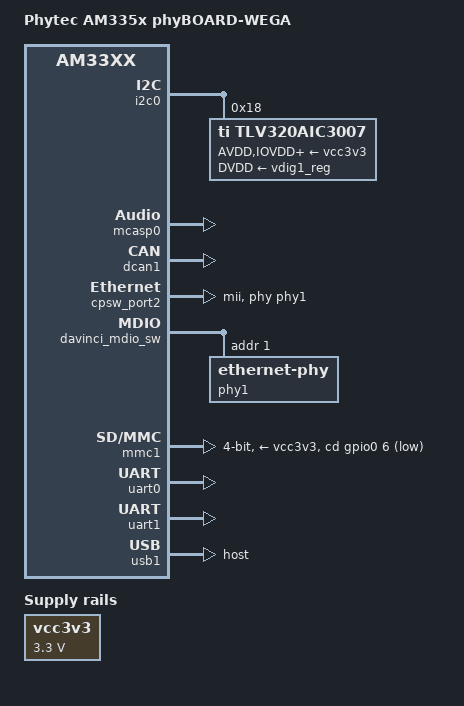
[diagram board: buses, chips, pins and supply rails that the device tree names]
/ {
	model = "Phytec AM335x phyBOARD-WEGA";
	compatible = "phytec,am335x-wega", "phytec,am335x-phycore-som", "ti,am33xx";
	sound: sound {
		compatible = "simple-audio-card";
		simple-audio-card,name = "snd-wega";
		simple-audio-card,format = "i2s";
		simple-audio-card,bitclock-master = <&sound_iface_main>;
		simple-audio-card,frame-master = <&sound_iface_main>;
		simple-audio-card,mclk-fs = <32>;
		simple-audio-card,widgets =
					"Line", "Line In",
					"Line", "Line Out",
					"Speaker", "Speaker";
		simple-audio-card,routing =
					"Line Out", "LLOUT",
					"Line Out", "RLOUT",
					"Speaker", "SPOP",
					"Speaker", "SPOM",
					"LINE1L", "Line In",
					"LINE1R", "Line In";
		simple-audio-card,cpu {
			sound-dai = <&mcasp0>;
		};
		sound_iface_main: simple-audio-card,codec {
			sound-dai = <&tlv320aic3007>;
			clocks = <&mcasp0_fck>;
		};
	};
	vcc3v3: fixedregulator1 {
		compatible = "regulator-fixed";
		regulator-name = "vcc3v3";
		regulator-min-microvolt = <3300000>;
		regulator-max-microvolt = <3300000>;
		regulator-boot-on;
	};
};
&am33xx_pinmux {
	mcasp0_pins: pinmux-mcasp0-pins {
		pinctrl-single,pins = <
			AM33XX_PADCONF(AM335X_PIN_MCASP0_AHCLKX, PIN_OUTPUT_PULLDOWN, MUX_MODE0)
			AM33XX_PADCONF(AM335X_PIN_MCASP0_ACLKX, PIN_INPUT_PULLDOWN, MUX_MODE0)
			AM33XX_PADCONF(AM335X_PIN_MCASP0_FSX, PIN_INPUT_PULLDOWN, MUX_MODE0)
			AM33XX_PADCONF(AM335X_PIN_MCASP0_AXR0, PIN_INPUT_PULLDOWN, MUX_MODE0)
			AM33XX_PADCONF(AM335X_PIN_MCASP0_AXR1, PIN_OUTPUT_PULLDOWN, MUX_MODE0)
		>;
	};
};
&i2c0 {
	tlv320aic3007: tlv320aic3007@18 {
		#sound-dai-cells = <0>;
		compatible = "ti,tlv320aic3007";
		reg = <0x18>;
		AVDD-supply = <&vcc3v3>;
		IOVDD-supply = <&vcc3v3>;
		DRVDD-supply = <&vcc3v3>;
		DVDD-supply = <&vdig1_reg>;
		status = "okay";
	};
};
&mcasp0 {
	#sound-dai-cells = <0>;
	pinctrl-names = "default";
	pinctrl-0 = <&mcasp0_pins>;
	op-mode = <0>;  
	tdm-slots = <2>;
	serial-dir = <
		2 1 0 0  
	>;
	tx-num-evt = <16>;
	rx-num-evt = <16>;
	status = "okay";
};
&am33xx_pinmux {
	dcan1_pins: pinmux-dcan1-pins {
		pinctrl-single,pins = <
			AM33XX_PADCONF(AM335X_PIN_UART0_CTSN, PIN_OUTPUT_PULLUP, MUX_MODE2)  
			AM33XX_PADCONF(AM335X_PIN_UART0_RTSN, PIN_INPUT_PULLUP, MUX_MODE2)  
		>;
	};
};
&dcan1 {
	pinctrl-names = "default";
	pinctrl-0 = <&dcan1_pins>;
	status = "okay";
};
&am33xx_pinmux {
	ethernet1_pins: pinmux-ethernet1-pins {
		pinctrl-single,pins = <
			AM33XX_PADCONF(AM335X_PIN_GPMC_A0, PIN_OUTPUT, MUX_MODE1)		 
			AM33XX_PADCONF(AM335X_PIN_GPMC_A1, PIN_INPUT_PULLDOWN, MUX_MODE1)	 
			AM33XX_PADCONF(AM335X_PIN_GPMC_A2, PIN_OUTPUT, MUX_MODE1)		 
			AM33XX_PADCONF(AM335X_PIN_GPMC_A3, PIN_OUTPUT, MUX_MODE1)		 
			AM33XX_PADCONF(AM335X_PIN_GPMC_A4, PIN_OUTPUT, MUX_MODE1)		 
			AM33XX_PADCONF(AM335X_PIN_GPMC_A5, PIN_OUTPUT, MUX_MODE1)		 
			AM33XX_PADCONF(AM335X_PIN_GPMC_A6, PIN_INPUT_PULLDOWN, MUX_MODE1)	 
			AM33XX_PADCONF(AM335X_PIN_GPMC_A7, PIN_INPUT_PULLDOWN, MUX_MODE1)	 
			AM33XX_PADCONF(AM335X_PIN_GPMC_A8, PIN_INPUT_PULLDOWN, MUX_MODE1)	 
			AM33XX_PADCONF(AM335X_PIN_GPMC_A9, PIN_INPUT_PULLDOWN, MUX_MODE1)	 
			AM33XX_PADCONF(AM335X_PIN_GPMC_A10, PIN_INPUT_PULLDOWN, MUX_MODE1)	 
			AM33XX_PADCONF(AM335X_PIN_GPMC_A11, PIN_INPUT_PULLDOWN, MUX_MODE1)	 
			AM33XX_PADCONF(AM335X_PIN_GPMC_WPN, PIN_INPUT_PULLDOWN, MUX_MODE1)	 
			AM33XX_PADCONF(AM335X_PIN_GPMC_BEN1, PIN_INPUT_PULLDOWN, MUX_MODE1)	 
		>;
	};
};
&cpsw_port2 {
	status = "okay";
	phy-handle = <&phy1>;
	phy-mode = "mii";
	ti,dual-emac-pvid = <2>;
};
&davinci_mdio_sw {
	phy1: ethernet-phy@1 {
		reg = <1>;
	};
};
&mac_sw {
	pinctrl-names = "default";
	pinctrl-0 = <&ethernet0_pins &ethernet1_pins>;
};
&am33xx_pinmux {
	mmc1_pins: pinmux-mmc1-pins {
		pinctrl-single,pins = <
			AM33XX_PADCONF(AM335X_PIN_MMC0_DAT3, PIN_INPUT_PULLUP, MUX_MODE0)
			AM33XX_PADCONF(AM335X_PIN_MMC0_DAT2, PIN_INPUT_PULLUP, MUX_MODE0)
			AM33XX_PADCONF(AM335X_PIN_MMC0_DAT1, PIN_INPUT_PULLUP, MUX_MODE0)
			AM33XX_PADCONF(AM335X_PIN_MMC0_DAT0, PIN_INPUT_PULLUP, MUX_MODE0)
			AM33XX_PADCONF(AM335X_PIN_MMC0_CLK, PIN_INPUT_PULLUP, MUX_MODE0)
			AM33XX_PADCONF(AM335X_PIN_MMC0_CMD, PIN_INPUT_PULLUP, MUX_MODE0)
			AM33XX_PADCONF(AM335X_PIN_SPI0_CS1, PIN_INPUT_PULLUP, MUX_MODE7)	 
		>;
	};
};
&mmc1 {
	vmmc-supply = <&vcc3v3>;
	bus-width = <4>;
	pinctrl-names = "default";
	pinctrl-0 = <&mmc1_pins>;
	cd-gpios = <&gpio0 6 GPIO_ACTIVE_LOW>;
	status = "okay";
};
&vdig1_reg {
	regulator-boot-on;
	regulator-always-on;
};
&am33xx_pinmux {
	uart0_pins: pinmux-uart0-pins {
		pinctrl-single,pins = <
			AM33XX_PADCONF(AM335X_PIN_UART0_RXD, PIN_INPUT_PULLUP, MUX_MODE0)
			AM33XX_PADCONF(AM335X_PIN_UART0_TXD, PIN_OUTPUT_PULLDOWN, MUX_MODE0)
		>;
	};
	uart1_pins: pinmux-uart1-pins {
		pinctrl-single,pins = <
			AM33XX_PADCONF(AM335X_PIN_UART1_RXD, PIN_INPUT_PULLUP, MUX_MODE0)
			AM33XX_PADCONF(AM335X_PIN_UART1_TXD, PIN_OUTPUT_PULLDOWN, MUX_MODE0)
			AM33XX_PADCONF(AM335X_PIN_UART1_CTSN, PIN_INPUT, MUX_MODE0)
			AM33XX_PADCONF(AM335X_PIN_UART1_RTSN, PIN_OUTPUT_PULLDOWN, MUX_MODE0)
		>;
	};
};
&uart0 {
	pinctrl-names = "default";
	pinctrl-0 = <&uart0_pins>;
	status = "okay";
};
&uart1 {
	pinctrl-names = "default";
	pinctrl-0 = <&uart1_pins>;
	status = "okay";
};
&usb1 {
	dr_mode = "host";
};
